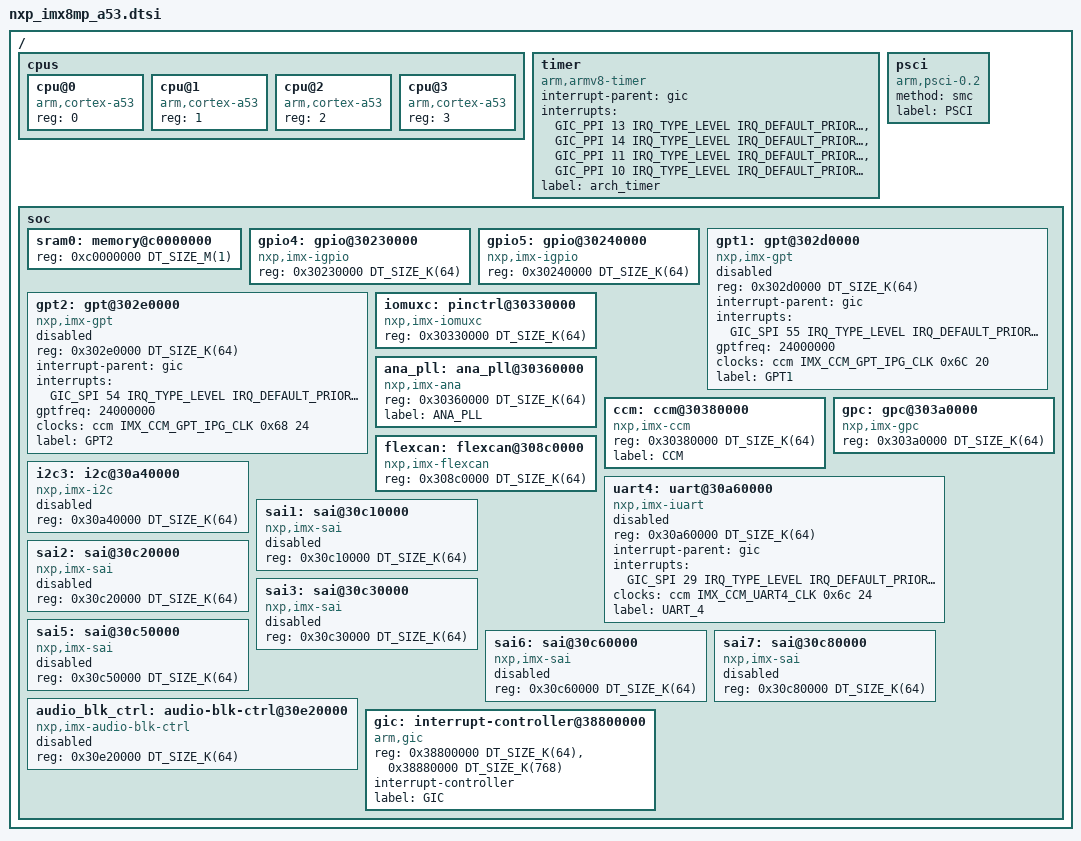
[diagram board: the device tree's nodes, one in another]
/*
 * Copyright 2022 NXP
 *
 * SPDX-License-Identifier: Apache-2.0
 */

#include <arm64/armv8-a.dtsi>
#include <dt-bindings/interrupt-controller/arm-gic.h>
#include <dt-bindings/clock/imx_ccm.h>
#include <mem.h>

/ {
	cpus {
		#address-cells = <1>;
		#size-cells = <0>;

		cpu@0 {
			device_type = "cpu";
			compatible = "arm,cortex-a53";
			reg = <0>;
		};

		cpu@1 {
			device_type = "cpu";
			compatible = "arm,cortex-a53";
			reg = <1>;
		};

		cpu@2 {
			device_type = "cpu";
			compatible = "arm,cortex-a53";
			reg = <2>;
		};

		cpu@3 {
			device_type = "cpu";
			compatible = "arm,cortex-a53";
			reg = <3>;
		};
	};

	timer {
		compatible = "arm,armv8-timer";
		interrupt-parent = <&gic>;
		interrupts = <GIC_PPI 13 IRQ_TYPE_LEVEL
			      IRQ_DEFAULT_PRIORITY>,
			     <GIC_PPI 14 IRQ_TYPE_LEVEL
			      IRQ_DEFAULT_PRIORITY>,
			     <GIC_PPI 11 IRQ_TYPE_LEVEL
			      IRQ_DEFAULT_PRIORITY>,
			     <GIC_PPI 10 IRQ_TYPE_LEVEL
			      IRQ_DEFAULT_PRIORITY>;
		label = "arch_timer";
	};

	psci {
		compatible = "arm,psci-0.2";
		method = "smc";
		label = "PSCI";
	};

	soc {
		sram0: memory@c0000000 {
			reg = <0xc0000000 DT_SIZE_M(1)>;
		};

		gpio4: gpio@30230000 {
			compatible = "nxp,imx-igpio";
			reg = <0x30230000 DT_SIZE_K(64)>;
		};

		gpio5: gpio@30240000 {
			compatible = "nxp,imx-igpio";
			reg = <0x30240000 DT_SIZE_K(64)>;
		};

		gpt1: gpt@302d0000 {
			compatible = "nxp,imx-gpt";
			reg = <0x302d0000 DT_SIZE_K(64)>;
			interrupt-parent = <&gic>;
			interrupts = <GIC_SPI 55 IRQ_TYPE_LEVEL
				IRQ_DEFAULT_PRIORITY>;
			gptfreq = <24000000>;
			clocks = <&ccm IMX_CCM_GPT_IPG_CLK 0x6C 20>;
			label = "GPT1";
			status = "disabled";
		};

		gpt2: gpt@302e0000 {
			compatible = "nxp,imx-gpt";
			reg = <0x302e0000 DT_SIZE_K(64)>;
			interrupt-parent = <&gic>;
			interrupts = <GIC_SPI 54 IRQ_TYPE_LEVEL
				IRQ_DEFAULT_PRIORITY>;
			gptfreq = <24000000>;
			clocks = <&ccm IMX_CCM_GPT_IPG_CLK 0x68 24>;
			label = "GPT2";
			status = "disabled";
		};

		iomuxc: pinctrl@30330000 {
			compatible = "nxp,imx-iomuxc";
			reg = <0x30330000 DT_SIZE_K(64)>;
		};

		ana_pll: ana_pll@30360000 {
			compatible = "nxp,imx-ana";
			reg = <0x30360000 DT_SIZE_K(64)>;
			label = "ANA_PLL";
		};

		ccm: ccm@30380000 {
			compatible = "nxp,imx-ccm";
			reg = <0x30380000 DT_SIZE_K(64)>;
			label = "CCM";
			#clock-cells = <3>;
		};

		gpc: gpc@303a0000 {
			compatible = "nxp,imx-gpc";
			reg = <0x303a0000 DT_SIZE_K(64)>;
		};

		flexcan: flexcan@308c0000 {
			compatible = "nxp,imx-flexcan";
			reg = <0x308c0000 DT_SIZE_K(64)>;
		};

		i2c3: i2c@30a40000 {
			compatible = "nxp,imx-i2c";
			reg = <0x30a40000 DT_SIZE_K(64)>;
			status = "disabled";
		};

		uart4: uart@30a60000 {
			compatible = "nxp,imx-iuart";
			reg = <0x30a60000 DT_SIZE_K(64)>;
			interrupt-parent = <&gic>;
			interrupts = <GIC_SPI 29 IRQ_TYPE_LEVEL
				      IRQ_DEFAULT_PRIORITY>;
			clocks = <&ccm IMX_CCM_UART4_CLK 0x6c 24>;
			label = "UART_4";
			status = "disabled";
		};

		sai1: sai@30c10000 {
			compatible = "nxp,imx-sai";
			reg = <0x30c10000 DT_SIZE_K(64)>;
			status = "disabled";
		};

		sai2: sai@30c20000 {
			compatible = "nxp,imx-sai";
			reg = <0x30c20000 DT_SIZE_K(64)>;
			status = "disabled";
		};

		sai3: sai@30c30000 {
			compatible = "nxp,imx-sai";
			reg = <0x30c30000 DT_SIZE_K(64)>;
			status = "disabled";
		};

		sai5: sai@30c50000 {
			compatible = "nxp,imx-sai";
			reg = <0x30c50000 DT_SIZE_K(64)>;
			status = "disabled";
		};

		sai6: sai@30c60000 {
			compatible = "nxp,imx-sai";
			reg = <0x30c60000 DT_SIZE_K(64)>;
			status = "disabled";
		};

		sai7: sai@30c80000 {
			compatible = "nxp,imx-sai";
			reg = <0x30c80000 DT_SIZE_K(64)>;
			status = "disabled";
		};

		audio_blk_ctrl: audio-blk-ctrl@30e20000 {
			compatible = "nxp,imx-audio-blk-ctrl";
			reg = <0x30e20000 DT_SIZE_K(64)>;
			status = "disabled";
		};

		gic: interrupt-controller@38800000 {
			compatible = "arm,gic";
			reg = <0x38800000 DT_SIZE_K(64)>, /* GICD */
			      <0x38880000 DT_SIZE_K(768)>; /* GICR */
			interrupt-controller;
			#interrupt-cells = <4>;
			label = "GIC";
			status = "okay";
		};
	};
};
